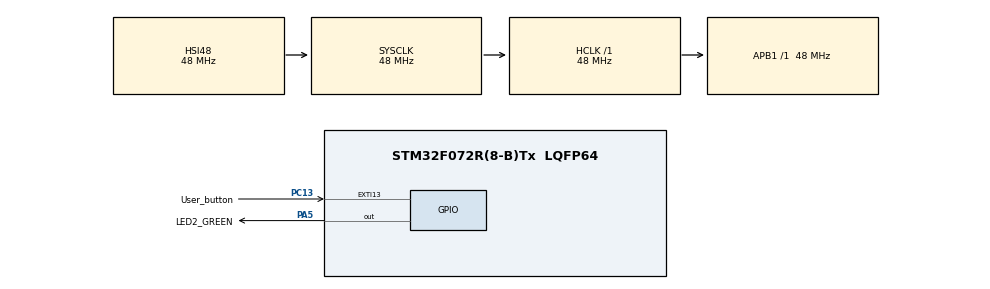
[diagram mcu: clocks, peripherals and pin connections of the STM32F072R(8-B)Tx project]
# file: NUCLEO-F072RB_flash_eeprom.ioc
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Mcu.Family=STM32F0
Mcu.Name=STM32F072R(8-B)Tx
Mcu.Package=LQFP64
NVIC.EXTI4_15_IRQn=true\:0\:0\:false\:false\:true
PA13.Mode=Serial_Wire
PA13.Signal=SYS_SWDIO
PA14.Mode=Serial_Wire
PA14.Signal=SYS_SWCLK
PA5.GPIO_Label=LED2_GREEN
PA5.Signal=GPIO_Output
PC13.GPIO_Label=User_button
PC13.GPIO_ModeDefaultEXTI=GPIO_MODE_IT_FALLING
PC13.Signal=GPXTI13
ProjectManager.HeapSize=0x200
ProjectManager.StackSize=0x400
ProjectManager.TargetToolchain=EWARM
RCC.AHBFreq_Value=48000000
RCC.APB1Freq_Value=48000000
RCC.APB1TimFreq_Value=48000000
RCC.HCLKFreq_Value=48000000
RCC.SYSCLKFreq_VALUE=48000000
RCC.SYSCLKSource=RCC_SYSCLKSOURCE_HSI48
board=NUCLEO-F072RB_flash_eeprom

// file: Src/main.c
/**
  ******************************************************************************
  * File Name          : main.c
  * Description        : Main program body
  ******************************************************************************
  ** This notice applies to any and all portions of this file
  * that are not between comment pairs USER CODE BEGIN and
  * USER CODE END. Other portions of this file, whether
  * inserted by the user or by software development tools
  * are owned by their respective copyright owners.
  *
  * COPYRIGHT(c) 2017 STMicroelectronics
  *
  * Redistribution and use in source and binary forms, with or without modification,
  * are permitted provided that the following conditions are met:
  *   1. Redistributions of source code must retain the above copyright notice,
  *      this list of conditions and the following disclaimer.
  *   2. Redistributions in binary form must reproduce the above copyright notice,
  *      this list of conditions and the following disclaimer in the documentation
  *      and/or other materials provided with the distribution.
  *   3. Neither the name of STMicroelectronics nor the names of its contributors
  *      may be used to endorse or promote products derived from this software
  *      without specific prior written permission.
  *
  * THIS SOFTWARE IS PROVIDED BY THE COPYRIGHT HOLDERS AND CONTRIBUTORS "AS IS"
  * AND ANY EXPRESS OR IMPLIED WARRANTIES, INCLUDING, BUT NOT LIMITED TO, THE
  * IMPLIED WARRANTIES OF MERCHANTABILITY AND FITNESS FOR A PARTICULAR PURPOSE ARE
  * DISCLAIMED. IN NO EVENT SHALL THE COPYRIGHT HOLDER OR CONTRIBUTORS BE LIABLE
  * FOR ANY DIRECT, INDIRECT, INCIDENTAL, SPECIAL, EXEMPLARY, OR CONSEQUENTIAL
  * DAMAGES (INCLUDING, BUT NOT LIMITED TO, PROCUREMENT OF SUBSTITUTE GOODS OR
  * SERVICES; LOSS OF USE, DATA, OR PROFITS; OR BUSINESS INTERRUPTION) HOWEVER
  * CAUSED AND ON ANY THEORY OF LIABILITY, WHETHER IN CONTRACT, STRICT LIABILITY,
  * OR TORT (INCLUDING NEGLIGENCE OR OTHERWISE) ARISING IN ANY WAY OUT OF THE USE
  * OF THIS SOFTWARE, EVEN IF ADVISED OF THE POSSIBILITY OF SUCH DAMAGE.
  *
  ******************************************************************************
  */
#include "main.h"
#include "stm32f0xx_hal.h"
#include "gpio.h"

/* USER CODE BEGIN Includes */
//------------------------------------------------------------------------------
/* Projeto    : NUCLEO-F072RB_flash_eeprom
 * MCU        : STM32F072RB (NUCLEO-F072RB)
 * Copyright  : Atribuição (CC BY 4.0) Diego Moreno
 * Versão     : 1.0.0
 * Data	      : 10/09/2016
 * Descrição  : Flash como EEPROM. Grava 6 bytes e depois lê os 6 bytes.
 *		NUCLEO-F072RB Schematics - http://migre.me/tVEOR
 */

/* Includes */

/* Defines */
#define PAGE_63    0x0801F800

//------------------------------------------------------------------------------
/* USER CODE END Includes */

/* USER CODE BEGIN PV */
/* Private variables ---------------------------------------------------------*/
volatile uint32_t Address = 0;
volatile uint16_t RAM_read[3];
/* USER CODE END PV */

void SystemClock_Config(void);

/* USER CODE BEGIN PFP */
/* Private function prototypes -----------------------------------------------*/

/* USER CODE END PFP */

int main(void)
{

  /* MCU Configuration----------------------------------------------------------*/

  /* Reset of all peripherals, Initializes the Flash interface and the Systick. */
  HAL_Init();

  /* Configure the system clock */
  SystemClock_Config();

  /* Initialize all configured peripherals */
  MX_GPIO_Init();

  /* USER CODE BEGIN 2 */

  //Gravar
  HAL_FLASH_Unlock();
  FLASH_PageErase(PAGE_63);
  HAL_FLASH_Program(FLASH_TYPEPROGRAM_HALFWORD, PAGE_63 +  0, 0x1234);
  HAL_FLASH_Program(FLASH_TYPEPROGRAM_HALFWORD, PAGE_63 +  2, 0x5678);
  HAL_FLASH_Program(FLASH_TYPEPROGRAM_HALFWORD, PAGE_63 +  4, 0x9ABC);
  HAL_FLASH_Lock();

  //Ler
  Address = PAGE_63;
  RAM_read[0] = *(uint16_t*)Address;
  Address = Address + 2;
  RAM_read[1] = *(uint16_t*)Address;
  Address = Address + 2;
  RAM_read[2] = *(uint16_t*)Address;

  /* USER CODE END 2 */

  /* Infinite loop */
  while (1)
  {

  }

}

/** System Clock Configuration
*/
void SystemClock_Config(void)
{

  RCC_OscInitTypeDef RCC_OscInitStruct;
  RCC_ClkInitTypeDef RCC_ClkInitStruct;

    /**Initializes the CPU, AHB and APB busses clocks
    */
  RCC_OscInitStruct.OscillatorType = RCC_OSCILLATORTYPE_HSI48;
  RCC_OscInitStruct.HSI48State = RCC_HSI48_ON;
  RCC_OscInitStruct.PLL.PLLState = RCC_PLL_NONE;
  if (HAL_RCC_OscConfig(&RCC_OscInitStruct) != HAL_OK)
  {
    _Error_Handler(__FILE__, __LINE__);
  }

    /**Initializes the CPU, AHB and APB busses clocks
    */
  RCC_ClkInitStruct.ClockType = RCC_CLOCKTYPE_HCLK|RCC_CLOCKTYPE_SYSCLK
                              |RCC_CLOCKTYPE_PCLK1;
  RCC_ClkInitStruct.SYSCLKSource = RCC_SYSCLKSOURCE_HSI48;
  RCC_ClkInitStruct.AHBCLKDivider = RCC_SYSCLK_DIV1;
  RCC_ClkInitStruct.APB1CLKDivider = RCC_HCLK_DIV1;

  if (HAL_RCC_ClockConfig(&RCC_ClkInitStruct, FLASH_LATENCY_1) != HAL_OK)
  {
    _Error_Handler(__FILE__, __LINE__);
  }

    /**Configure the Systick interrupt time
    */
  HAL_SYSTICK_Config(HAL_RCC_GetHCLKFreq()/1000);

    /**Configure the Systick
    */
  HAL_SYSTICK_CLKSourceConfig(SYSTICK_CLKSOURCE_HCLK);

  /* SysTick_IRQn interrupt configuration */
  HAL_NVIC_SetPriority(SysTick_IRQn, 0, 0);
}

void _Error_Handler(char * file, int line)
{
  while(1)
  {
  }
}

/************************ (C) COPYRIGHT STMicroelectronics *****END OF FILE****/
